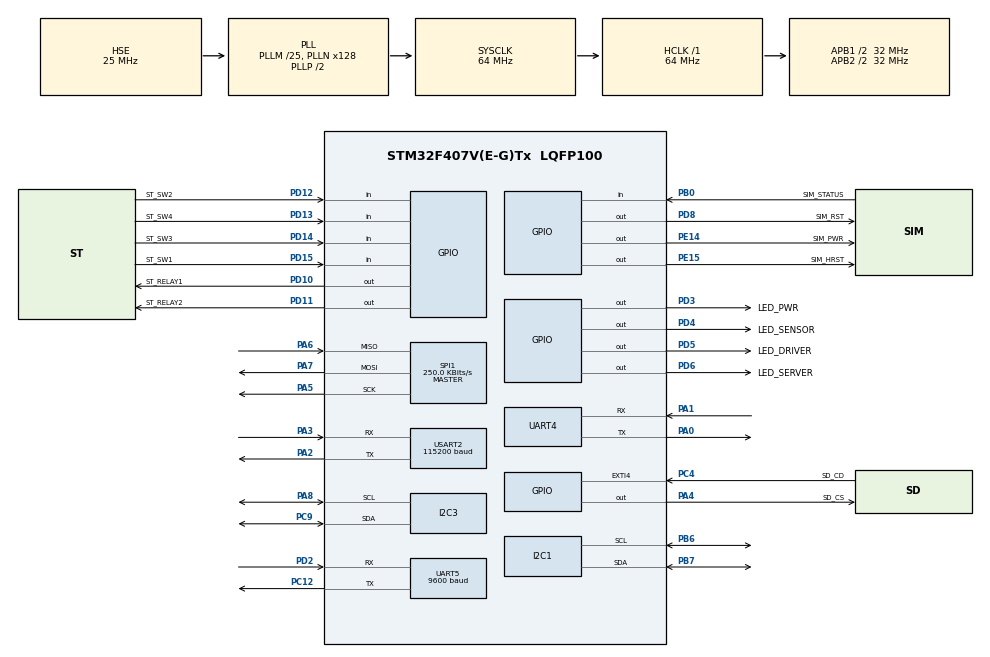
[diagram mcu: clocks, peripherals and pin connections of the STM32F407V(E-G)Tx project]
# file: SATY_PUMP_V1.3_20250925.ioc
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Dma.Request0=USART2_RX
Dma.Request1=SPI1_RX
Dma.Request2=UART5_RX
Dma.SPI1_RX.1.Direction=DMA_PERIPH_TO_MEMORY
Dma.SPI1_RX.1.FIFOMode=DMA_FIFOMODE_DISABLE
Dma.SPI1_RX.1.Instance=DMA2_Stream0
Dma.SPI1_RX.1.MemDataAlignment=DMA_MDATAALIGN_BYTE
Dma.SPI1_RX.1.MemInc=DMA_MINC_ENABLE
Dma.SPI1_RX.1.Mode=DMA_NORMAL
Dma.SPI1_RX.1.PeriphDataAlignment=DMA_PDATAALIGN_BYTE
Dma.SPI1_RX.1.PeriphInc=DMA_PINC_DISABLE
Dma.SPI1_RX.1.Priority=DMA_PRIORITY_LOW
Dma.UART5_RX.2.Direction=DMA_PERIPH_TO_MEMORY
Dma.UART5_RX.2.FIFOMode=DMA_FIFOMODE_DISABLE
Dma.UART5_RX.2.Instance=DMA1_Stream0
Dma.UART5_RX.2.MemDataAlignment=DMA_MDATAALIGN_BYTE
Dma.UART5_RX.2.MemInc=DMA_MINC_ENABLE
Dma.UART5_RX.2.Mode=DMA_NORMAL
Dma.UART5_RX.2.PeriphDataAlignment=DMA_PDATAALIGN_BYTE
Dma.UART5_RX.2.PeriphInc=DMA_PINC_DISABLE
Dma.UART5_RX.2.Priority=DMA_PRIORITY_LOW
Dma.USART2_RX.0.Direction=DMA_PERIPH_TO_MEMORY
Dma.USART2_RX.0.FIFOMode=DMA_FIFOMODE_DISABLE
Dma.USART2_RX.0.Instance=DMA1_Stream5
Dma.USART2_RX.0.MemDataAlignment=DMA_MDATAALIGN_BYTE
Dma.USART2_RX.0.MemInc=DMA_MINC_ENABLE
Dma.USART2_RX.0.Mode=DMA_NORMAL
Dma.USART2_RX.0.PeriphDataAlignment=DMA_PDATAALIGN_BYTE
Dma.USART2_RX.0.PeriphInc=DMA_PINC_DISABLE
Dma.USART2_RX.0.Priority=DMA_PRIORITY_LOW
FATFS._MAX_SS=512
FATFS._USE_LFN=0
FREERTOS.Tasks01=defaultTask,25,512,StartDefaultTask,Default,NULL,Dynamic,NULL,NULL
FREERTOS.configGENERATE_RUN_TIME_STATS=1
FREERTOS.configRECORD_STACK_HIGH_ADDRESS=1
FREERTOS.configUSE_STATS_FORMATTING_FUNCTIONS=1
Mcu.Family=STM32F4
Mcu.Name=STM32F407V(E-G)Tx
Mcu.Package=LQFP100
NVIC.DMA1_Stream0_IRQn=true\:5\:0\:false\:false\:true\:true\:false\:true\:true
NVIC.DMA1_Stream5_IRQn=true\:5\:0\:false\:false\:true\:true\:false\:true\:true
NVIC.DMA2_Stream0_IRQn=true\:5\:0\:false\:false\:true\:true\:false\:true\:true
NVIC.EXTI4_IRQn=true\:5\:0\:false\:false\:true\:true\:true\:true\:true
NVIC.PriorityGroup=NVIC_PRIORITYGROUP_4
NVIC.TIM2_IRQn=true\:5\:0\:false\:false\:true\:true\:true\:true\:true
NVIC.TIM6_DAC_IRQn=true\:15\:0\:false\:false\:true\:false\:false\:true\:true
NVIC.TIM7_IRQn=true\:5\:0\:false\:false\:true\:true\:true\:true\:true
NVIC.TimeBase=TIM6_DAC_IRQn
NVIC.TimeBaseIP=TIM6
NVIC.UART4_IRQn=true\:5\:0\:false\:false\:true\:true\:true\:true\:true
NVIC.UART5_IRQn=true\:5\:0\:false\:false\:true\:true\:true\:true\:true
PA0-WKUP.Mode=Asynchronous
PA0-WKUP.Signal=UART4_TX
PA1.Mode=Asynchronous
PA1.Signal=UART4_RX
PA13.Mode=Serial_Wire
PA13.Signal=SYS_JTMS-SWDIO
PA14.Mode=Serial_Wire
PA14.Signal=SYS_JTCK-SWCLK
PA2.Mode=Asynchronous
PA2.Signal=USART2_TX
PA3.Mode=Asynchronous
PA3.Signal=USART2_RX
PA4.GPIO_Label=SD_CS
PA4.GPIO_PuPd=GPIO_PULLUP
PA4.Signal=GPIO_Output
PA5.Mode=Full_Duplex_Master
PA5.Signal=SPI1_SCK
PA6.Mode=Full_Duplex_Master
PA6.Signal=SPI1_MISO
PA7.Mode=Full_Duplex_Master
PA7.Signal=SPI1_MOSI
PA8.Mode=I2C
PA8.Signal=I2C3_SCL
PB0.GPIO_Label=SIM_STATUS
PB0.Signal=GPIO_Input
PB6.Mode=I2C
PB6.Signal=I2C1_SCL
PB7.Mode=I2C
PB7.Signal=I2C1_SDA
PC12.GPIO_PuPd=GPIO_NOPULL
PC12.Mode=Asynchronous
PC12.Signal=UART5_TX
PC4.GPIO_Label=SD_CD
PC4.GPIO_ModeDefaultEXTI=GPIO_MODE_IT_RISING_FALLING
PC4.GPIO_PuPd=GPIO_PULLUP
PC4.Signal=GPXTI4
PC9.Mode=I2C
PC9.Signal=I2C3_SDA
PD10.GPIO_Label=ST_RELAY1
PD10.Signal=GPIO_Output
PD11.GPIO_Label=ST_RELAY2
PD11.Signal=GPIO_Output
PD12.GPIO_Label=ST_SW2
PD12.Signal=GPIO_Input
PD13.GPIO_Label=ST_SW4
PD13.Signal=GPIO_Input
PD14.GPIO_Label=ST_SW3
PD14.Signal=GPIO_Input
PD15.GPIO_Label=ST_SW1
PD15.Signal=GPIO_Input
PD2.GPIO_PuPd=GPIO_NOPULL
PD2.Mode=Asynchronous
PD2.Signal=UART5_RX
PD3.GPIO_Label=LED_PWR
PD3.Signal=GPIO_Output
PD4.GPIO_Label=LED_SENSOR
PD4.Signal=GPIO_Output
PD5.GPIO_Label=LED_DRIVER
PD5.Signal=GPIO_Output
PD6.GPIO_Label=LED_SERVER
PD6.Signal=GPIO_Output
PD8.GPIO_Label=SIM_RST
PD8.Signal=GPIO_Output
PE14.GPIO_Label=SIM_PWR
PE14.Signal=GPIO_Output
PE15.GPIO_Label=SIM_HRST
PE15.Signal=GPIO_Output
PH0-OSC_IN.Mode=HSE-External-Oscillator
PH0-OSC_IN.Signal=RCC_OSC_IN
PH1-OSC_OUT.Mode=HSE-External-Oscillator
PH1-OSC_OUT.Signal=RCC_OSC_OUT
ProjectManager.HeapSize=0x200
ProjectManager.StackSize=0x400
ProjectManager.TargetToolchain=STM32CubeIDE
RCC.48MHZClocksFreq_Value=32000000
RCC.AHBFreq_Value=64000000
RCC.APB1CLKDivider=RCC_HCLK_DIV2
RCC.APB1Freq_Value=32000000
RCC.APB1TimFreq_Value=64000000
RCC.APB2CLKDivider=RCC_HCLK_DIV2
RCC.APB2Freq_Value=32000000
RCC.APB2TimFreq_Value=64000000
RCC.CortexFreq_Value=64000000
RCC.HCLKFreq_Value=64000000
RCC.HSE_VALUE=25000000
RCC.HSI_VALUE=16000000
RCC.LSE_VALUE=32768
RCC.PLLM=25
RCC.PLLN=128
RCC.PLLSourceVirtual=RCC_PLLSOURCE_HSE
RCC.SYSCLKFreq_VALUE=64000000
RCC.SYSCLKSource=RCC_SYSCLKSOURCE_PLLCLK
RCC.VCOOutputFreq_Value=128000000
SPI1.BaudRatePrescaler=SPI_BAUDRATEPRESCALER_128
SPI1.CalculateBaudRate=250.0 KBits/s
SPI1.Direction=SPI_DIRECTION_2LINES
SPI1.Mode=SPI_MODE_MASTER
SPI1.VirtualType=VM_MASTER
TIM2.Period=49
TIM2.Prescaler=63999
TIM7.Prescaler=63
UART4.VirtualMode=Asynchronous
UART5.BaudRate=9600
UART5.VirtualMode=Asynchronous
USART2.BaudRate=115200
USART2.VirtualMode=VM_ASYNC
VP_FATFS_VS_Generic.Mode=User_defined
VP_FREERTOS_VS_CMSIS_V2.Mode=CMSIS_V2
VP_SYS_VS_tim6.Mode=TIM6
VP_TIM2_VS_ClockSourceINT.Mode=Internal
VP_TIM7_VS_ClockSourceINT.Mode=Enable_Timer
board=custom

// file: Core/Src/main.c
/* USER CODE BEGIN Header */
/**
 ******************************************************************************
 * @file           : main.c
 * @brief          : Main program body
 ******************************************************************************
 * @attention
 *
 * Copyright (c) 2025 STMicroelectronics.
 * All rights reserved.
 *
 * This software is licensed under terms that can be found in the LICENSE file
 * in the root directory of this software component.
 * If no LICENSE file comes with this software, it is provided AS-IS.
 *
 ******************************************************************************
 */
/* USER CODE END Header */
#include "main.h"
#include "cmsis_os.h"
#include "fatfs.h"

/* USER CODE BEGIN Includes */
#include "../App/ChuongTrinhChinh.h"

/* USER CODE END Includes */

I2C_HandleTypeDef hi2c1;
I2C_HandleTypeDef hi2c3;

SPI_HandleTypeDef hspi1;
DMA_HandleTypeDef hdma_spi1_rx;

TIM_HandleTypeDef htim2;
TIM_HandleTypeDef htim7;

UART_HandleTypeDef huart4;
UART_HandleTypeDef huart5;
UART_HandleTypeDef huart2;
DMA_HandleTypeDef hdma_uart5_rx;
DMA_HandleTypeDef hdma_usart2_rx;

/* Definitions for defaultTask */
osThreadId_t defaultTaskHandle;
const osThreadAttr_t defaultTask_attributes = { .name = "defaultTask",
		.stack_size = 512 * 4, .priority = (osPriority_t) osPriorityNormal1, };
/* USER CODE BEGIN PV */
#include <stdio.h>
/* USER CODE END PV */

void SystemClock_Config(void);
static void MX_GPIO_Init(void);
static void MX_DMA_Init(void);
static void MX_USART2_UART_Init(void);
static void MX_UART4_Init(void);
static void MX_TIM2_Init(void);
static void MX_I2C1_Init(void);
static void MX_SPI1_Init(void);
static void MX_UART5_Init(void);
static void MX_I2C3_Init(void);
static void MX_TIM7_Init(void);
void StartDefaultTask(void *argument);

/* USER CODE BEGIN 0 */
/* USER CODE BEGIN 0 */
//uint8_t Scan_Address(void){
//    for(uint8_t i = 1; i < 128; i++){
//        // Quét tất cả các địa chỉ I2C
//        if(HAL_I2C_IsDeviceReady(&hi2c1, (i << 1), 1, 1000) == HAL_OK){
//            return i;
//        }
//    }
//    return 0; // Không tìm thấy
//}
/* USER CODE END 0 */
volatile char device_id_str[20];

void Get_STM32_DeviceID(void) {
    uint32_t uid_word0 = HAL_GetUIDw0();
    uint32_t uid_word2 = HAL_GetUIDw2();
    sprintf((char*)device_id_str, "%08X%05X", (unsigned int)uid_word0, (unsigned int)(uid_word2 & 0xFFFFF));
}
/* USER CODE END 0 */

int main(void) {

	/* MCU Configuration--------------------------------------------------------*/

	/* Reset of all peripherals, Initializes the Flash interface and the Systick. */
	HAL_Init();

	/* USER CODE BEGIN Init */
	Get_STM32_DeviceID();
	/* USER CODE END Init */

	/* Configure the system clock */
	SystemClock_Config();

	/* Initialize all configured peripherals */
	MX_GPIO_Init();
	MX_DMA_Init();
	MX_USART2_UART_Init();
	MX_UART4_Init();
	MX_TIM2_Init();
	MX_I2C1_Init();
	MX_SPI1_Init();
	MX_FATFS_Init();
	MX_UART5_Init();
	MX_I2C3_Init();
	MX_TIM7_Init();

	/* USER CODE BEGIN 2 */
//	uint8_t addr = Scan_Address();
//	extern uint16_t i2c_status;
//	if(HAL_I2C_IsDeviceReady(&hi2c1, (0x6B << 1), 5, 1000) == HAL_OK) {
//	    i2c_status = 1111;
//	} else {
//	    i2c_status =addr;
//	}
	/* USER CODE END 2 */

	/* Init scheduler */
	osKernelInitialize();
	KhoiTao();

	/* Create the thread(s) */
	/* creation of defaultTask */
	defaultTaskHandle = osThreadNew(StartDefaultTask, NULL,
			&defaultTask_attributes);

	/* Start scheduler */
	osKernelStart();

	/* We should never get here as control is now taken by the scheduler */

	/* Infinite loop */
	while (1) {

	}
}

void SystemClock_Config(void) {
	RCC_OscInitTypeDef RCC_OscInitStruct = { 0 };
	RCC_ClkInitTypeDef RCC_ClkInitStruct = { 0 };

	/** Configure the main internal regulator output voltage
	 */
	__HAL_RCC_PWR_CLK_ENABLE();
	__HAL_PWR_VOLTAGESCALING_CONFIG(PWR_REGULATOR_VOLTAGE_SCALE1);

	/** Initializes the RCC Oscillators according to the specified parameters
	 * in the RCC_OscInitTypeDef structure.
	 */
	RCC_OscInitStruct.OscillatorType = RCC_OSCILLATORTYPE_HSE;
	RCC_OscInitStruct.HSEState = RCC_HSE_ON;
	RCC_OscInitStruct.PLL.PLLState = RCC_PLL_ON;
	RCC_OscInitStruct.PLL.PLLSource = RCC_PLLSOURCE_HSE;
	RCC_OscInitStruct.PLL.PLLM = 25;
	RCC_OscInitStruct.PLL.PLLN = 128;
	RCC_OscInitStruct.PLL.PLLP = RCC_PLLP_DIV2;
	RCC_OscInitStruct.PLL.PLLQ = 4;
	if (HAL_RCC_OscConfig(&RCC_OscInitStruct) != HAL_OK) {
		Error_Handler();
	}

	/** Initializes the CPU, AHB and APB buses clocks
	 */
	RCC_ClkInitStruct.ClockType = RCC_CLOCKTYPE_HCLK | RCC_CLOCKTYPE_SYSCLK
			| RCC_CLOCKTYPE_PCLK1 | RCC_CLOCKTYPE_PCLK2;
	RCC_ClkInitStruct.SYSCLKSource = RCC_SYSCLKSOURCE_PLLCLK;
	RCC_ClkInitStruct.AHBCLKDivider = RCC_SYSCLK_DIV1;
	RCC_ClkInitStruct.APB1CLKDivider = RCC_HCLK_DIV2;
	RCC_ClkInitStruct.APB2CLKDivider = RCC_HCLK_DIV2;

	if (HAL_RCC_ClockConfig(&RCC_ClkInitStruct, FLASH_LATENCY_2) != HAL_OK) {
		Error_Handler();
	}
}

static void MX_I2C1_Init(void) {

	hi2c1.Instance = I2C1;
	hi2c1.Init.ClockSpeed = 100000;
	hi2c1.Init.DutyCycle = I2C_DUTYCYCLE_2;
	hi2c1.Init.OwnAddress1 = 0;
	hi2c1.Init.AddressingMode = I2C_ADDRESSINGMODE_7BIT;
	hi2c1.Init.DualAddressMode = I2C_DUALADDRESS_DISABLE;
	hi2c1.Init.OwnAddress2 = 0;
	hi2c1.Init.GeneralCallMode = I2C_GENERALCALL_DISABLE;
	hi2c1.Init.NoStretchMode = I2C_NOSTRETCH_DISABLE;
	if (HAL_I2C_Init(&hi2c1) != HAL_OK) {
		Error_Handler();
	}

}

static void MX_I2C3_Init(void) {

	hi2c3.Instance = I2C3;
	hi2c3.Init.ClockSpeed = 100000;
	hi2c3.Init.DutyCycle = I2C_DUTYCYCLE_2;
	hi2c3.Init.OwnAddress1 = 0;
	hi2c3.Init.AddressingMode = I2C_ADDRESSINGMODE_7BIT;
	hi2c3.Init.DualAddressMode = I2C_DUALADDRESS_DISABLE;
	hi2c3.Init.OwnAddress2 = 0;
	hi2c3.Init.GeneralCallMode = I2C_GENERALCALL_DISABLE;
	hi2c3.Init.NoStretchMode = I2C_NOSTRETCH_DISABLE;
	if (HAL_I2C_Init(&hi2c3) != HAL_OK) {
		Error_Handler();
	}

}

static void MX_SPI1_Init(void) {

	/* SPI1 parameter configuration*/
	hspi1.Instance = SPI1;
	hspi1.Init.Mode = SPI_MODE_MASTER;
	hspi1.Init.Direction = SPI_DIRECTION_2LINES;
	hspi1.Init.DataSize = SPI_DATASIZE_8BIT;
	hspi1.Init.CLKPolarity = SPI_POLARITY_LOW;
	hspi1.Init.CLKPhase = SPI_PHASE_1EDGE;
	hspi1.Init.NSS = SPI_NSS_SOFT;
	hspi1.Init.BaudRatePrescaler = SPI_BAUDRATEPRESCALER_128;
	hspi1.Init.FirstBit = SPI_FIRSTBIT_MSB;
	hspi1.Init.TIMode = SPI_TIMODE_DISABLE;
	hspi1.Init.CRCCalculation = SPI_CRCCALCULATION_DISABLE;
	hspi1.Init.CRCPolynomial = 10;
	if (HAL_SPI_Init(&hspi1) != HAL_OK) {
		Error_Handler();
	}

}

static void MX_TIM2_Init(void) {

	TIM_ClockConfigTypeDef sClockSourceConfig = { 0 };
	TIM_MasterConfigTypeDef sMasterConfig = { 0 };

	htim2.Instance = TIM2;
	htim2.Init.Prescaler = 63999;
	htim2.Init.CounterMode = TIM_COUNTERMODE_UP;
	htim2.Init.Period = 49;
	htim2.Init.ClockDivision = TIM_CLOCKDIVISION_DIV1;
	htim2.Init.AutoReloadPreload = TIM_AUTORELOAD_PRELOAD_DISABLE;
	if (HAL_TIM_Base_Init(&htim2) != HAL_OK) {
		Error_Handler();
	}
	sClockSourceConfig.ClockSource = TIM_CLOCKSOURCE_INTERNAL;
	if (HAL_TIM_ConfigClockSource(&htim2, &sClockSourceConfig) != HAL_OK) {
		Error_Handler();
	}
	sMasterConfig.MasterOutputTrigger = TIM_TRGO_RESET;
	sMasterConfig.MasterSlaveMode = TIM_MASTERSLAVEMODE_DISABLE;
	if (HAL_TIMEx_MasterConfigSynchronization(&htim2, &sMasterConfig)
			!= HAL_OK) {
		Error_Handler();
	}

}

static void MX_TIM7_Init(void) {

	TIM_MasterConfigTypeDef sMasterConfig = { 0 };

	htim7.Instance = TIM7;
	htim7.Init.Prescaler = 63;
	htim7.Init.CounterMode = TIM_COUNTERMODE_UP;
	htim7.Init.Period = 65535;
	htim7.Init.AutoReloadPreload = TIM_AUTORELOAD_PRELOAD_DISABLE;
	if (HAL_TIM_Base_Init(&htim7) != HAL_OK) {
		Error_Handler();
	}
	sMasterConfig.MasterOutputTrigger = TIM_TRGO_RESET;
	sMasterConfig.MasterSlaveMode = TIM_MASTERSLAVEMODE_DISABLE;
	if (HAL_TIMEx_MasterConfigSynchronization(&htim7, &sMasterConfig)
			!= HAL_OK) {
		Error_Handler();
	}

}

static void MX_UART4_Init(void) {

	huart4.Instance = UART4;
	huart4.Init.BaudRate = 115200;
	huart4.Init.WordLength = UART_WORDLENGTH_8B;
	huart4.Init.StopBits = UART_STOPBITS_1;
	huart4.Init.Parity = UART_PARITY_NONE;
	huart4.Init.Mode = UART_MODE_TX_RX;
	huart4.Init.HwFlowCtl = UART_HWCONTROL_NONE;
	huart4.Init.OverSampling = UART_OVERSAMPLING_16;
	if (HAL_UART_Init(&huart4) != HAL_OK) {
		Error_Handler();
	}

}

static void MX_UART5_Init(void) {

	huart5.Instance = UART5;
	huart5.Init.BaudRate = 9600;
	huart5.Init.WordLength = UART_WORDLENGTH_8B;
	huart5.Init.StopBits = UART_STOPBITS_1;
	huart5.Init.Parity = UART_PARITY_NONE;
	huart5.Init.Mode = UART_MODE_TX_RX;
	huart5.Init.HwFlowCtl = UART_HWCONTROL_NONE;
	huart5.Init.OverSampling = UART_OVERSAMPLING_16;
	if (HAL_UART_Init(&huart5) != HAL_OK) {
		Error_Handler();
	}

}

static void MX_USART2_UART_Init(void) {

	huart2.Instance = USART2;
	huart2.Init.BaudRate = 115200;
	huart2.Init.WordLength = UART_WORDLENGTH_8B;
	huart2.Init.StopBits = UART_STOPBITS_1;
	huart2.Init.Parity = UART_PARITY_NONE;
	huart2.Init.Mode = UART_MODE_TX_RX;
	huart2.Init.HwFlowCtl = UART_HWCONTROL_NONE;
	huart2.Init.OverSampling = UART_OVERSAMPLING_16;
	if (HAL_UART_Init(&huart2) != HAL_OK) {
		Error_Handler();
	}

}

static void MX_DMA_Init(void) {

	/* DMA controller clock enable */
	__HAL_RCC_DMA1_CLK_ENABLE();
	__HAL_RCC_DMA2_CLK_ENABLE();

	/* DMA interrupt init */
	/* DMA1_Stream0_IRQn interrupt configuration */
	HAL_NVIC_SetPriority(DMA1_Stream0_IRQn, 5, 0);
	HAL_NVIC_EnableIRQ(DMA1_Stream0_IRQn);
	/* DMA1_Stream5_IRQn interrupt configuration */
	HAL_NVIC_SetPriority(DMA1_Stream5_IRQn, 5, 0);
	HAL_NVIC_EnableIRQ(DMA1_Stream5_IRQn);
	/* DMA2_Stream0_IRQn interrupt configuration */
	HAL_NVIC_SetPriority(DMA2_Stream0_IRQn, 5, 0);
	HAL_NVIC_EnableIRQ(DMA2_Stream0_IRQn);

}

static void MX_GPIO_Init(void) {
	GPIO_InitTypeDef GPIO_InitStruct = { 0 };

	/* GPIO Ports Clock Enable */
	__HAL_RCC_GPIOE_CLK_ENABLE();
	__HAL_RCC_GPIOC_CLK_ENABLE();
	__HAL_RCC_GPIOH_CLK_ENABLE();
	__HAL_RCC_GPIOA_CLK_ENABLE();
	__HAL_RCC_GPIOB_CLK_ENABLE();
	__HAL_RCC_GPIOD_CLK_ENABLE();

	/*Configure GPIO pin Output Level */
	HAL_GPIO_WritePin(SD_CS_GPIO_Port, SD_CS_Pin, GPIO_PIN_RESET);

	/*Configure GPIO pin Output Level */
	HAL_GPIO_WritePin(GPIOE, SIM_PWR_Pin | SIM_HRST_Pin, GPIO_PIN_RESET);

	/*Configure GPIO pin Output Level */
	HAL_GPIO_WritePin(GPIOD,
			SIM_RST_Pin | ST_RELAY1_Pin | ST_RELAY2_Pin | LED_PWR_Pin
					| LED_SENSOR_Pin | LED_DRIVER_Pin | LED_SERVER_Pin,
			GPIO_PIN_RESET);

	/*Configure GPIO pins : PE2 PE3 PE4 PE5
	 PE6 PE7 PE8 PE9
	 PE10 PE11 PE12 PE13
	 PE0 PE1 */
	GPIO_InitStruct.Pin = GPIO_PIN_2 | GPIO_PIN_3 | GPIO_PIN_4 | GPIO_PIN_5
			| GPIO_PIN_6 | GPIO_PIN_7 | GPIO_PIN_8 | GPIO_PIN_9 | GPIO_PIN_10
			| GPIO_PIN_11 | GPIO_PIN_12 | GPIO_PIN_13 | GPIO_PIN_0 | GPIO_PIN_1;
	GPIO_InitStruct.Mode = GPIO_MODE_ANALOG;
	GPIO_InitStruct.Pull = GPIO_NOPULL;
	HAL_GPIO_Init(GPIOE, &GPIO_InitStruct);

	/*Configure GPIO pins : PC13 PC14 PC15 PC0
	 PC1 PC2 PC3 PC5
	 PC6 PC7 PC8 PC10
	 PC11 */
	GPIO_InitStruct.Pin = GPIO_PIN_13 | GPIO_PIN_14 | GPIO_PIN_15 | GPIO_PIN_0
			| GPIO_PIN_1 | GPIO_PIN_2 | GPIO_PIN_3 | GPIO_PIN_5 | GPIO_PIN_6
			| GPIO_PIN_7 | GPIO_PIN_8 | GPIO_PIN_10 | GPIO_PIN_11;
	GPIO_InitStruct.Mode = GPIO_MODE_ANALOG;
	GPIO_InitStruct.Pull = GPIO_NOPULL;
	HAL_GPIO_Init(GPIOC, &GPIO_InitStruct);

	/*Configure GPIO pin : SD_CS_Pin */
	GPIO_InitStruct.Pin = SD_CS_Pin;
	GPIO_InitStruct.Mode = GPIO_MODE_OUTPUT_PP;
	GPIO_InitStruct.Pull = GPIO_PULLUP;
	GPIO_InitStruct.Speed = GPIO_SPEED_FREQ_LOW;
	HAL_GPIO_Init(SD_CS_GPIO_Port, &GPIO_InitStruct);

	/*Configure GPIO pin : SD_CD_Pin */
	GPIO_InitStruct.Pin = SD_CD_Pin;
	GPIO_InitStruct.Mode = GPIO_MODE_IT_RISING_FALLING;
	GPIO_InitStruct.Pull = GPIO_PULLUP;
	HAL_GPIO_Init(SD_CD_GPIO_Port, &GPIO_InitStruct);

	/*Configure GPIO pin : SIM_STATUS_Pin */
	GPIO_InitStruct.Pin = SIM_STATUS_Pin;
	GPIO_InitStruct.Mode = GPIO_MODE_INPUT;
	GPIO_InitStruct.Pull = GPIO_NOPULL;
	HAL_GPIO_Init(SIM_STATUS_GPIO_Port, &GPIO_InitStruct);

	/*Configure GPIO pins : PB1 PB2 PB10 PB11
	 PB12 PB13 PB14 PB15
	 PB3 PB4 PB5 PB8
	 PB9 */
	GPIO_InitStruct.Pin = GPIO_PIN_1 | GPIO_PIN_2 | GPIO_PIN_10 | GPIO_PIN_11
			| GPIO_PIN_12 | GPIO_PIN_13 | GPIO_PIN_14 | GPIO_PIN_15 | GPIO_PIN_3
			| GPIO_PIN_4 | GPIO_PIN_5 | GPIO_PIN_8 | GPIO_PIN_9;
	GPIO_InitStruct.Mode = GPIO_MODE_ANALOG;
	GPIO_InitStruct.Pull = GPIO_NOPULL;
	HAL_GPIO_Init(GPIOB, &GPIO_InitStruct);

	/*Configure GPIO pins : SIM_PWR_Pin SIM_HRST_Pin */
	GPIO_InitStruct.Pin = SIM_PWR_Pin | SIM_HRST_Pin;
	GPIO_InitStruct.Mode = GPIO_MODE_OUTPUT_PP;
	GPIO_InitStruct.Pull = GPIO_NOPULL;
	GPIO_InitStruct.Speed = GPIO_SPEED_FREQ_LOW;
	HAL_GPIO_Init(GPIOE, &GPIO_InitStruct);

	/*Configure GPIO pins : SIM_RST_Pin ST_RELAY1_Pin ST_RELAY2_Pin LED_PWR_Pin
	 LED_SENSOR_Pin LED_DRIVER_Pin LED_SERVER_Pin */
	GPIO_InitStruct.Pin = SIM_RST_Pin | ST_RELAY1_Pin | ST_RELAY2_Pin
			| LED_PWR_Pin | LED_SENSOR_Pin | LED_DRIVER_Pin | LED_SERVER_Pin;
	GPIO_InitStruct.Mode = GPIO_MODE_OUTPUT_PP;
	GPIO_InitStruct.Pull = GPIO_NOPULL;
	GPIO_InitStruct.Speed = GPIO_SPEED_FREQ_LOW;
	HAL_GPIO_Init(GPIOD, &GPIO_InitStruct);

	/*Configure GPIO pins : PD9 PD0 PD1 PD7 */
	GPIO_InitStruct.Pin = GPIO_PIN_9 | GPIO_PIN_0 | GPIO_PIN_1 | GPIO_PIN_7;
	GPIO_InitStruct.Mode = GPIO_MODE_ANALOG;
	GPIO_InitStruct.Pull = GPIO_NOPULL;
	HAL_GPIO_Init(GPIOD, &GPIO_InitStruct);

	/*Configure GPIO pins : ST_SW2_Pin ST_SW4_Pin ST_SW3_Pin ST_SW1_Pin */
	GPIO_InitStruct.Pin = ST_SW2_Pin | ST_SW4_Pin | ST_SW3_Pin | ST_SW1_Pin;
	GPIO_InitStruct.Mode = GPIO_MODE_INPUT;
	GPIO_InitStruct.Pull = GPIO_NOPULL;
	HAL_GPIO_Init(GPIOD, &GPIO_InitStruct);

	/*Configure GPIO pins : PA9 PA10 PA11 PA12
	 PA15 */
	GPIO_InitStruct.Pin = GPIO_PIN_9 | GPIO_PIN_10 | GPIO_PIN_11 | GPIO_PIN_12
			| GPIO_PIN_15;
	GPIO_InitStruct.Mode = GPIO_MODE_ANALOG;
	GPIO_InitStruct.Pull = GPIO_NOPULL;
	HAL_GPIO_Init(GPIOA, &GPIO_InitStruct);

	/* EXTI interrupt init*/
	HAL_NVIC_SetPriority(EXTI4_IRQn, 5, 0);
	HAL_NVIC_EnableIRQ(EXTI4_IRQn);

}

void StartDefaultTask(void *argument) {
	for (;;) {
		osDelay(1);
	}
}

void Error_Handler(void) {
	__disable_irq();
	while (1) {
	}
}

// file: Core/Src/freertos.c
/* USER CODE BEGIN Header */
/**
 ******************************************************************************
 * File Name          : freertos.c
 * Description        : Code for freertos applications
 ******************************************************************************
 * @attention
 *
 * Copyright (c) 2025 STMicroelectronics.
 * All rights reserved.
 *
 * This software is licensed under terms that can be found in the LICENSE file
 * in the root directory of this software component.
 * If no LICENSE file comes with this software, it is provided AS-IS.
 *
 ******************************************************************************
 */
/* USER CODE END Header */

#include "FreeRTOS.h"
#include "task.h"
#include "main.h"

/* USER CODE BEGIN Variables */
volatile unsigned long ulStartTimerStick;
extern TIM_HandleTypeDef htim7;
/* USER CODE END Variables */

/* Hook prototypes */
void configureTimerForRunTimeStats(void);
unsigned long getRunTimeCounterValue(void);

/* USER CODE BEGIN 1 */
/* Functions needed when configGENERATE_RUN_TIME_STATS is on */
__weak void configureTimerForRunTimeStats(void) {
	ulStartTimerStick = 0;
	HAL_TIM_Base_Start_IT(&htim7);
}

__weak unsigned long getRunTimeCounterValue(void) {
	return ulStartTimerStick;
}
/* USER CODE END 1 */
